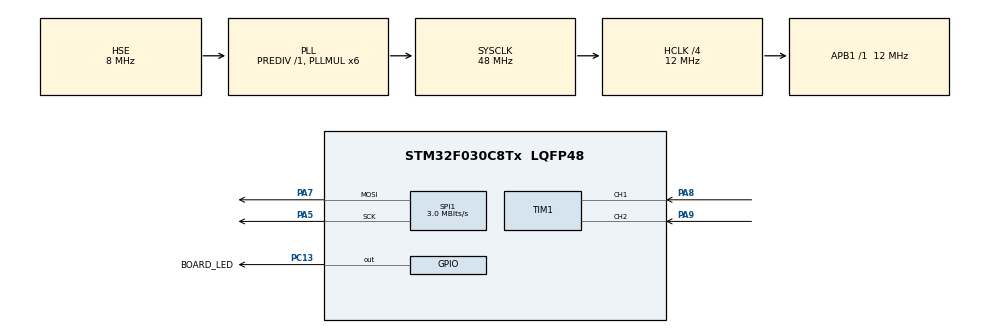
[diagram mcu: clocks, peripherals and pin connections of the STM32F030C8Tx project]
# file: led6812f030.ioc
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Dma.Request0=SPI1_TX
Dma.SPI1_TX.0.Direction=DMA_MEMORY_TO_PERIPH
Dma.SPI1_TX.0.Instance=DMA1_Channel3
Dma.SPI1_TX.0.MemDataAlignment=DMA_MDATAALIGN_BYTE
Dma.SPI1_TX.0.MemInc=DMA_MINC_ENABLE
Dma.SPI1_TX.0.Mode=DMA_NORMAL
Dma.SPI1_TX.0.PeriphDataAlignment=DMA_PDATAALIGN_BYTE
Dma.SPI1_TX.0.PeriphInc=DMA_PINC_DISABLE
Dma.SPI1_TX.0.Priority=DMA_PRIORITY_HIGH
FREERTOS.MEMORY_ALLOCATION=1
FREERTOS.Tasks01=mainTask,0,256,StartMainTask,As weak,NULL,Static,defaultTaskBuffer,defaultTaskControlBlock;ctrlTask,0,128,StartCtrlTask,As external,NULL,Static,myTask02Buffer,myTask02ControlBlock
FREERTOS.configCHECK_FOR_STACK_OVERFLOW=2
FREERTOS.configENABLE_BACKWARD_COMPATIBILITY=0
FREERTOS.configGENERATE_RUN_TIME_STATS=1
FREERTOS.configRECORD_STACK_HIGH_ADDRESS=1
FREERTOS.configUSE_STATS_FORMATTING_FUNCTIONS=1
FREERTOS.configUSE_TRACE_FACILITY=1
Mcu.Family=STM32F0
Mcu.Name=STM32F030C8Tx
Mcu.Package=LQFP48
NVIC.DMA1_Channel2_3_IRQn=true\:3\:0\:false\:false\:true\:true\:false\:true\:true
NVIC.TIM6_IRQn=true\:3\:0\:false\:false\:true\:false\:false\:true\:true
NVIC.TimeBase=TIM6_IRQn
NVIC.TimeBaseIP=TIM6
PA13.Mode=Serial_Wire
PA13.Signal=SYS_SWDIO
PA14.Mode=Serial_Wire
PA14.Signal=SYS_SWCLK
PA5.Mode=TX_Only_Simplex_Unidirect_Master
PA5.Signal=SPI1_SCK
PA7.Mode=TX_Only_Simplex_Unidirect_Master
PA7.Signal=SPI1_MOSI
PA8.GPIO_PuPd=GPIO_PULLUP
PA8.Signal=S_TIM1_CH1
PA9.GPIO_PuPd=GPIO_PULLUP
PA9.Signal=S_TIM1_CH2
PC13.GPIO_Label=BOARD_LED
PC13.Signal=GPIO_Output
PC14-OSC32_IN.Mode=LSE-External-Oscillator
PC14-OSC32_IN.Signal=RCC_OSC32_IN
PC15-OSC32_OUT.Mode=LSE-External-Oscillator
PC15-OSC32_OUT.Signal=RCC_OSC32_OUT
PF0-OSC_IN.Mode=HSE-External-Oscillator
PF0-OSC_IN.Signal=RCC_OSC_IN
PF1-OSC_OUT.Mode=HSE-External-Oscillator
PF1-OSC_OUT.Signal=RCC_OSC_OUT
ProjectManager.HeapSize=0x200
ProjectManager.StackSize=0x400
ProjectManager.TargetToolchain=STM32CubeIDE
RCC.AHBCLKDivider=RCC_SYSCLK_DIV4
RCC.AHBFreq_Value=12000000
RCC.APB1Freq_Value=12000000
RCC.APB1TimFreq_Value=12000000
RCC.HCLKFreq_Value=12000000
RCC.PLLMUL=RCC_PLL_MUL6
RCC.PLLSourceVirtual=RCC_PLLSOURCE_HSE
RCC.RTCClockSelection=RCC_RTCCLKSOURCE_LSE
RCC.SYSCLKFreq_VALUE=48000000
RCC.SYSCLKSource=RCC_SYSCLKSOURCE_PLLCLK
SH.S_TIM1_CH1.0=TIM1_CH1,Encoder_Interface
SH.S_TIM1_CH2.0=TIM1_CH2,Encoder_Interface
SPI1.BaudRatePrescaler=SPI_BAUDRATEPRESCALER_4
SPI1.CalculateBaudRate=3.0 MBits/s
SPI1.DataSize=SPI_DATASIZE_8BIT
SPI1.Direction=SPI_DIRECTION_2LINES
SPI1.Mode=SPI_MODE_MASTER
SPI1.NSSPMode=SPI_NSS_PULSE_DISABLE
SPI1.VirtualType=VM_MASTER
TIM1.EncoderMode=TIM_ENCODERMODE_TI12
TIM1.IC1Filter=2
TIM1.IC2Filter=2
VP_FREERTOS_VS_CMSIS_V1.Mode=CMSIS_V1
VP_RTC_VS_RTC_Activate.Mode=RTC_Enabled
VP_RTC_VS_RTC_Calendar.Mode=RTC_Calendar
VP_SYS_VS_tim6.Mode=TIM6
board=custom

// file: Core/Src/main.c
/* USER CODE BEGIN Header */
/**
  ******************************************************************************
  * @file           : main.c
  * @brief          : Main program body
  ******************************************************************************
  * @attention
  *
  * Copyright (c) 2023 STMicroelectronics.
  * All rights reserved.
  *
  * This software is licensed under terms that can be found in the LICENSE file
  * in the root directory of this software component.
  * If no LICENSE file comes with this software, it is provided AS-IS.
  *
  ******************************************************************************
  */
/* USER CODE END Header */
#include "main.h"
#include "cmsis_os.h"

/* USER CODE BEGIN Includes */
#include "../../../Led/ledtask.h"
/* USER CODE END Includes */

RTC_HandleTypeDef hrtc;

SPI_HandleTypeDef hspi1;
DMA_HandleTypeDef hdma_spi1_tx;

TIM_HandleTypeDef htim1;

osThreadId mainTaskHandle;
uint32_t defaultTaskBuffer[ 256 ];
osStaticThreadDef_t defaultTaskControlBlock;
osThreadId ctrlTaskHandle;
uint32_t myTask02Buffer[ 128 ];
osStaticThreadDef_t myTask02ControlBlock;

void SystemClock_Config(void);
static void MX_GPIO_Init(void);
static void MX_DMA_Init(void);
static void MX_RTC_Init(void);
static void MX_SPI1_Init(void);
static void MX_TIM1_Init(void);
void StartMainTask(void const * argument);
extern void StartCtrlTask(void const * argument);

int main(void)
{

  /* MCU Configuration--------------------------------------------------------*/

  /* Reset of all peripherals, Initializes the Flash interface and the Systick. */
  HAL_Init();

  /* Configure the system clock */
  SystemClock_Config();

  /* Initialize all configured peripherals */
  MX_GPIO_Init();
  MX_DMA_Init();
  MX_RTC_Init();
  MX_SPI1_Init();
  MX_TIM1_Init();

  /* Create the thread(s) */
  /* definition and creation of mainTask */
  osThreadStaticDef(mainTask, StartMainTask, osPriorityNormal, 0, 256, defaultTaskBuffer, &defaultTaskControlBlock);
  mainTaskHandle = osThreadCreate(osThread(mainTask), NULL);

  /* definition and creation of ctrlTask */
  osThreadStaticDef(ctrlTask, StartCtrlTask, osPriorityNormal, 0, 128, myTask02Buffer, &myTask02ControlBlock);
  ctrlTaskHandle = osThreadCreate(osThread(ctrlTask), NULL);

  /* Start scheduler */
  osKernelStart();

  /* We should never get here as control is now taken by the scheduler */
  /* Infinite loop */
  while (1)
  {

  }
}

void SystemClock_Config(void)
{
  RCC_OscInitTypeDef RCC_OscInitStruct = {0};
  RCC_ClkInitTypeDef RCC_ClkInitStruct = {0};
  RCC_PeriphCLKInitTypeDef PeriphClkInit = {0};

  /** Configure LSE Drive Capability
  */
  HAL_PWR_EnableBkUpAccess();
  __HAL_RCC_LSEDRIVE_CONFIG(RCC_LSEDRIVE_HIGH);

  /** Initializes the RCC Oscillators according to the specified parameters
  * in the RCC_OscInitTypeDef structure.
  */
  RCC_OscInitStruct.OscillatorType = RCC_OSCILLATORTYPE_HSE|RCC_OSCILLATORTYPE_LSE;
  RCC_OscInitStruct.HSEState = RCC_HSE_ON;
  RCC_OscInitStruct.LSEState = RCC_LSE_ON;
  RCC_OscInitStruct.PLL.PLLState = RCC_PLL_ON;
  RCC_OscInitStruct.PLL.PLLSource = RCC_PLLSOURCE_HSE;
  RCC_OscInitStruct.PLL.PLLMUL = RCC_PLL_MUL6;
  RCC_OscInitStruct.PLL.PREDIV = RCC_PREDIV_DIV1;
  if (HAL_RCC_OscConfig(&RCC_OscInitStruct) != HAL_OK)
  {
    Error_Handler();
  }

  /** Initializes the CPU, AHB and APB buses clocks
  */
  RCC_ClkInitStruct.ClockType = RCC_CLOCKTYPE_HCLK|RCC_CLOCKTYPE_SYSCLK
                              |RCC_CLOCKTYPE_PCLK1;
  RCC_ClkInitStruct.SYSCLKSource = RCC_SYSCLKSOURCE_PLLCLK;
  RCC_ClkInitStruct.AHBCLKDivider = RCC_SYSCLK_DIV4;
  RCC_ClkInitStruct.APB1CLKDivider = RCC_HCLK_DIV1;

  if (HAL_RCC_ClockConfig(&RCC_ClkInitStruct, FLASH_LATENCY_1) != HAL_OK)
  {
    Error_Handler();
  }
  PeriphClkInit.PeriphClockSelection = RCC_PERIPHCLK_RTC;
  PeriphClkInit.RTCClockSelection = RCC_RTCCLKSOURCE_LSE;
  if (HAL_RCCEx_PeriphCLKConfig(&PeriphClkInit) != HAL_OK)
  {
    Error_Handler();
  }
}

static void MX_RTC_Init(void)
{

  RTC_TimeTypeDef sTime = {0};
  RTC_DateTypeDef sDate = {0};

  /** Initialize RTC Only
  */
  hrtc.Instance = RTC;
  hrtc.Init.HourFormat = RTC_HOURFORMAT_24;
  hrtc.Init.AsynchPrediv = 127;
  hrtc.Init.SynchPrediv = 255;
  hrtc.Init.OutPut = RTC_OUTPUT_DISABLE;
  hrtc.Init.OutPutPolarity = RTC_OUTPUT_POLARITY_HIGH;
  hrtc.Init.OutPutType = RTC_OUTPUT_TYPE_OPENDRAIN;
  if (HAL_RTC_Init(&hrtc) != HAL_OK)
  {
    Error_Handler();
  }

  /** Initialize RTC and set the Time and Date
  */
  sTime.Hours = 0x0;
  sTime.Minutes = 0x0;
  sTime.Seconds = 0x0;
  sTime.DayLightSaving = RTC_DAYLIGHTSAVING_NONE;
  sTime.StoreOperation = RTC_STOREOPERATION_RESET;
  if (HAL_RTC_SetTime(&hrtc, &sTime, RTC_FORMAT_BCD) != HAL_OK)
  {
    Error_Handler();
  }
  sDate.WeekDay = RTC_WEEKDAY_MONDAY;
  sDate.Month = RTC_MONTH_JANUARY;
  sDate.Date = 0x1;
  sDate.Year = 0x0;

  if (HAL_RTC_SetDate(&hrtc, &sDate, RTC_FORMAT_BCD) != HAL_OK)
  {
    Error_Handler();
  }

}

static void MX_SPI1_Init(void)
{

  /* SPI1 parameter configuration*/
  hspi1.Instance = SPI1;
  hspi1.Init.Mode = SPI_MODE_MASTER;
  hspi1.Init.Direction = SPI_DIRECTION_2LINES;
  hspi1.Init.DataSize = SPI_DATASIZE_8BIT;
  hspi1.Init.CLKPolarity = SPI_POLARITY_LOW;
  hspi1.Init.CLKPhase = SPI_PHASE_1EDGE;
  hspi1.Init.NSS = SPI_NSS_SOFT;
  hspi1.Init.BaudRatePrescaler = SPI_BAUDRATEPRESCALER_4;
  hspi1.Init.FirstBit = SPI_FIRSTBIT_MSB;
  hspi1.Init.TIMode = SPI_TIMODE_DISABLE;
  hspi1.Init.CRCCalculation = SPI_CRCCALCULATION_DISABLE;
  hspi1.Init.CRCPolynomial = 7;
  hspi1.Init.CRCLength = SPI_CRC_LENGTH_DATASIZE;
  hspi1.Init.NSSPMode = SPI_NSS_PULSE_DISABLE;
  if (HAL_SPI_Init(&hspi1) != HAL_OK)
  {
    Error_Handler();
  }

}

static void MX_TIM1_Init(void)
{

  TIM_Encoder_InitTypeDef sConfig = {0};
  TIM_MasterConfigTypeDef sMasterConfig = {0};

  htim1.Instance = TIM1;
  htim1.Init.Prescaler = 0;
  htim1.Init.CounterMode = TIM_COUNTERMODE_UP;
  htim1.Init.Period = 65535;
  htim1.Init.ClockDivision = TIM_CLOCKDIVISION_DIV1;
  htim1.Init.RepetitionCounter = 0;
  htim1.Init.AutoReloadPreload = TIM_AUTORELOAD_PRELOAD_DISABLE;
  sConfig.EncoderMode = TIM_ENCODERMODE_TI12;
  sConfig.IC1Polarity = TIM_ICPOLARITY_RISING;
  sConfig.IC1Selection = TIM_ICSELECTION_DIRECTTI;
  sConfig.IC1Prescaler = TIM_ICPSC_DIV1;
  sConfig.IC1Filter = 2;
  sConfig.IC2Polarity = TIM_ICPOLARITY_RISING;
  sConfig.IC2Selection = TIM_ICSELECTION_DIRECTTI;
  sConfig.IC2Prescaler = TIM_ICPSC_DIV1;
  sConfig.IC2Filter = 2;
  if (HAL_TIM_Encoder_Init(&htim1, &sConfig) != HAL_OK)
  {
    Error_Handler();
  }
  sMasterConfig.MasterOutputTrigger = TIM_TRGO_RESET;
  sMasterConfig.MasterSlaveMode = TIM_MASTERSLAVEMODE_DISABLE;
  if (HAL_TIMEx_MasterConfigSynchronization(&htim1, &sMasterConfig) != HAL_OK)
  {
    Error_Handler();
  }

}

static void MX_DMA_Init(void)
{

  /* DMA controller clock enable */
  __HAL_RCC_DMA1_CLK_ENABLE();

  /* DMA interrupt init */
  /* DMA1_Channel2_3_IRQn interrupt configuration */
  HAL_NVIC_SetPriority(DMA1_Channel2_3_IRQn, 3, 0);
  HAL_NVIC_EnableIRQ(DMA1_Channel2_3_IRQn);

}

static void MX_GPIO_Init(void)
{
  GPIO_InitTypeDef GPIO_InitStruct = {0};

  /* GPIO Ports Clock Enable */
  __HAL_RCC_GPIOC_CLK_ENABLE();
  __HAL_RCC_GPIOF_CLK_ENABLE();
  __HAL_RCC_GPIOA_CLK_ENABLE();

  /*Configure GPIO pin Output Level */
  HAL_GPIO_WritePin(BOARD_LED_GPIO_Port, BOARD_LED_Pin, GPIO_PIN_RESET);

  /*Configure GPIO pin : BOARD_LED_Pin */
  GPIO_InitStruct.Pin = BOARD_LED_Pin;
  GPIO_InitStruct.Mode = GPIO_MODE_OUTPUT_PP;
  GPIO_InitStruct.Pull = GPIO_NOPULL;
  GPIO_InitStruct.Speed = GPIO_SPEED_FREQ_LOW;
  HAL_GPIO_Init(BOARD_LED_GPIO_Port, &GPIO_InitStruct);

}

__weak void StartMainTask(void const * argument)
{
  for(;;)
  {
    osDelay(1);
  }
}

void HAL_TIM_PeriodElapsedCallback(TIM_HandleTypeDef *htim)
{
  if (htim->Instance == TIM6) {
    HAL_IncTick();
  }
  /* USER CODE BEGIN Callback 1 */
  if (htim->Instance == TIM6) {
	  static int t = 0;
	  static int nwake=0;
	  t++;
	  // 100 Hz polling for main task
	  if ((0==(t%10)) && mainTaskHandle) {
		  BaseType_t higher=0;
		  nwake++;

		  xTaskNotifyFromISR(mainTaskHandle, NOTIF_TICK, eSetBits, &higher);
		  portYIELD_FROM_ISR(higher);
	  }
	  // 10Hz polling for ctrl task
	  if ((2==(t%100)) && ctrlTaskHandle) {
		  BaseType_t higher=0;
		  xTaskNotifyFromISR(ctrlTaskHandle, NOTIF_TICK, eSetBits, &higher);
		  portYIELD_FROM_ISR(higher);
	  }
  }
  /* USER CODE END Callback 1 */
}

void Error_Handler(void)
{
  __disable_irq();
  while (1)
  {
  }
}

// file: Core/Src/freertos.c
/* USER CODE BEGIN Header */
/**
  ******************************************************************************
  * File Name          : freertos.c
  * Description        : Code for freertos applications
  ******************************************************************************
  * @attention
  *
  * Copyright (c) 2023 STMicroelectronics.
  * All rights reserved.
  *
  * This software is licensed under terms that can be found in the LICENSE file
  * in the root directory of this software component.
  * If no LICENSE file comes with this software, it is provided AS-IS.
  *
  ******************************************************************************
  */
/* USER CODE END Header */

#include "FreeRTOS.h"
#include "task.h"
#include "main.h"

/* GetIdleTaskMemory prototype (linked to static allocation support) */
void vApplicationGetIdleTaskMemory( StaticTask_t **ppxIdleTaskTCBBuffer, StackType_t **ppxIdleTaskStackBuffer, uint32_t *pulIdleTaskStackSize );

/* Hook prototypes */
void configureTimerForRunTimeStats(void);
unsigned long getRunTimeCounterValue(void);
void vApplicationStackOverflowHook(TaskHandle_t xTask, signed char *pcTaskName);

/* USER CODE BEGIN 1 */
/* Functions needed when configGENERATE_RUN_TIME_STATS is on */
__weak void configureTimerForRunTimeStats(void)
{

}

__weak unsigned long getRunTimeCounterValue(void)
{
return 0;
}
/* USER CODE END 1 */

/* USER CODE BEGIN 4 */
__weak void vApplicationStackOverflowHook(TaskHandle_t xTask, signed char *pcTaskName)
{
   /* Run time stack overflow checking is performed if
   configCHECK_FOR_STACK_OVERFLOW is defined to 1 or 2. This hook function is
   called if a stack overflow is detected. */
}
/* USER CODE END 4 */

/* USER CODE BEGIN GET_IDLE_TASK_MEMORY */
static StaticTask_t xIdleTaskTCBBuffer;
static StackType_t xIdleStack[configMINIMAL_STACK_SIZE];

void vApplicationGetIdleTaskMemory( StaticTask_t **ppxIdleTaskTCBBuffer, StackType_t **ppxIdleTaskStackBuffer, uint32_t *pulIdleTaskStackSize )
{
  *ppxIdleTaskTCBBuffer = &xIdleTaskTCBBuffer;
  *ppxIdleTaskStackBuffer = &xIdleStack[0];
  *pulIdleTaskStackSize = configMINIMAL_STACK_SIZE;
  /* place for user code */
}
/* USER CODE END GET_IDLE_TASK_MEMORY */
